# R5FSS_COMMON0_R5FSS_COMMON0_COMPARE_CFG_05B00000h register map
Vendor: Texas Instruments
Peripheral module from a debugger description file (folder AM275x).
Registers are 32-bit, access per field, reset 0x0 unless marked. A register's access mark holds for its fields unless they carry their own. Offsets are as the file gives them; lines under a group give offsets from that group; [hi:lo] are bit positions; {n}, {i} and the like mark numbered series; 'fields as' and 'values as' point back to an identical list; <NAME> marks a mode.

## R5FSS_COMMON0_COMPARE_CFG
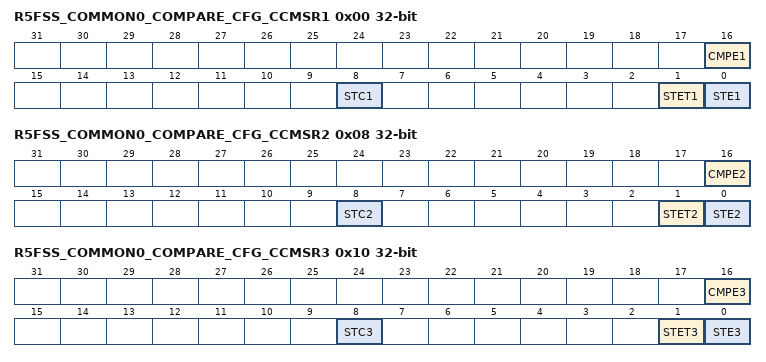
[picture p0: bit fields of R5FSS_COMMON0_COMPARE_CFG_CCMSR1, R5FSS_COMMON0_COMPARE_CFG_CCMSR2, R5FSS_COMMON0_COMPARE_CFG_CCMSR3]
0x00 R5FSS_COMMON0_COMPARE_CFG_CCMSR1 — Shows the Error and Self test Status of the CPU CPU Compare block.
  [16] CMPE1 rw — This is the CMPE1 field Reset Source: mod_g_rst_n
  [8] STC1 ro — This is the STC1 field Reset Source: mod_g_rst_n
  [1] STET1 ro — This is the STET1 field Reset Source: mod_g_rst_n
  [0] STE1 ro — This is the STE1 field Reset Source: mod_g_rst_n
0x04 R5FSS_COMMON0_COMPARE_CFG_CCMKEYR1 — Selects Operating mode of CPU Compare block.
  [3:0] MKEY1 rw — This is the MKEY1 field Reset Source: mod_g_rst_n
0x08 R5FSS_COMMON0_COMPARE_CFG_CCMSR2 — Shows the Error and Self test Status of the CPU CPU Compare block.
  [16] CMPE2 rw — This is the CMPE2 field Reset Source: mod_g_rst_n
  [8] STC2 ro — This is the STC2 field Reset Source: mod_g_rst_n
  [1] STET2 ro — This is the STET2 field Reset Source: mod_g_rst_n
  [0] STE2 ro — This is the STE2 field Reset Source: mod_g_rst_n
0x0C R5FSS_COMMON0_COMPARE_CFG_CCMKEYR2 — Selects Operating mode of CPU Compare block.
  [3:0] MKEY2 rw — This is the MKEY2 field Reset Source: mod_g_rst_n
0x10 R5FSS_COMMON0_COMPARE_CFG_CCMSR3 — Shows the Error and Self test Status of the CPU CPU Compare block.
  [16] CMPE3 rw — This is the CMPE3 field Reset Source: mod_g_rst_n
  [8] STC3 ro — This is the STC3 field Reset Source: mod_g_rst_n
  [1] STET3 ro — This is the STET3 field Reset Source: mod_g_rst_n
  [0] STE3 ro — This is the STE3 field Reset Source: mod_g_rst_n
0x14 R5FSS_COMMON0_COMPARE_CFG_CCMKEYR3 — Selects Operating mode of CPU Compare block.
  [3:0] MKEY3 rw — This is the MKEY3 field Reset Source: mod_g_rst_n
0x18 R5FSS_COMMON0_COMPARE_CFG_CCMPOLCNTRL — Selects Operating mode of CPU Compare block.
  [7:0] POL_INV rw — This is the Polarity Inversion field Reset Source: mod_g_rst_n
